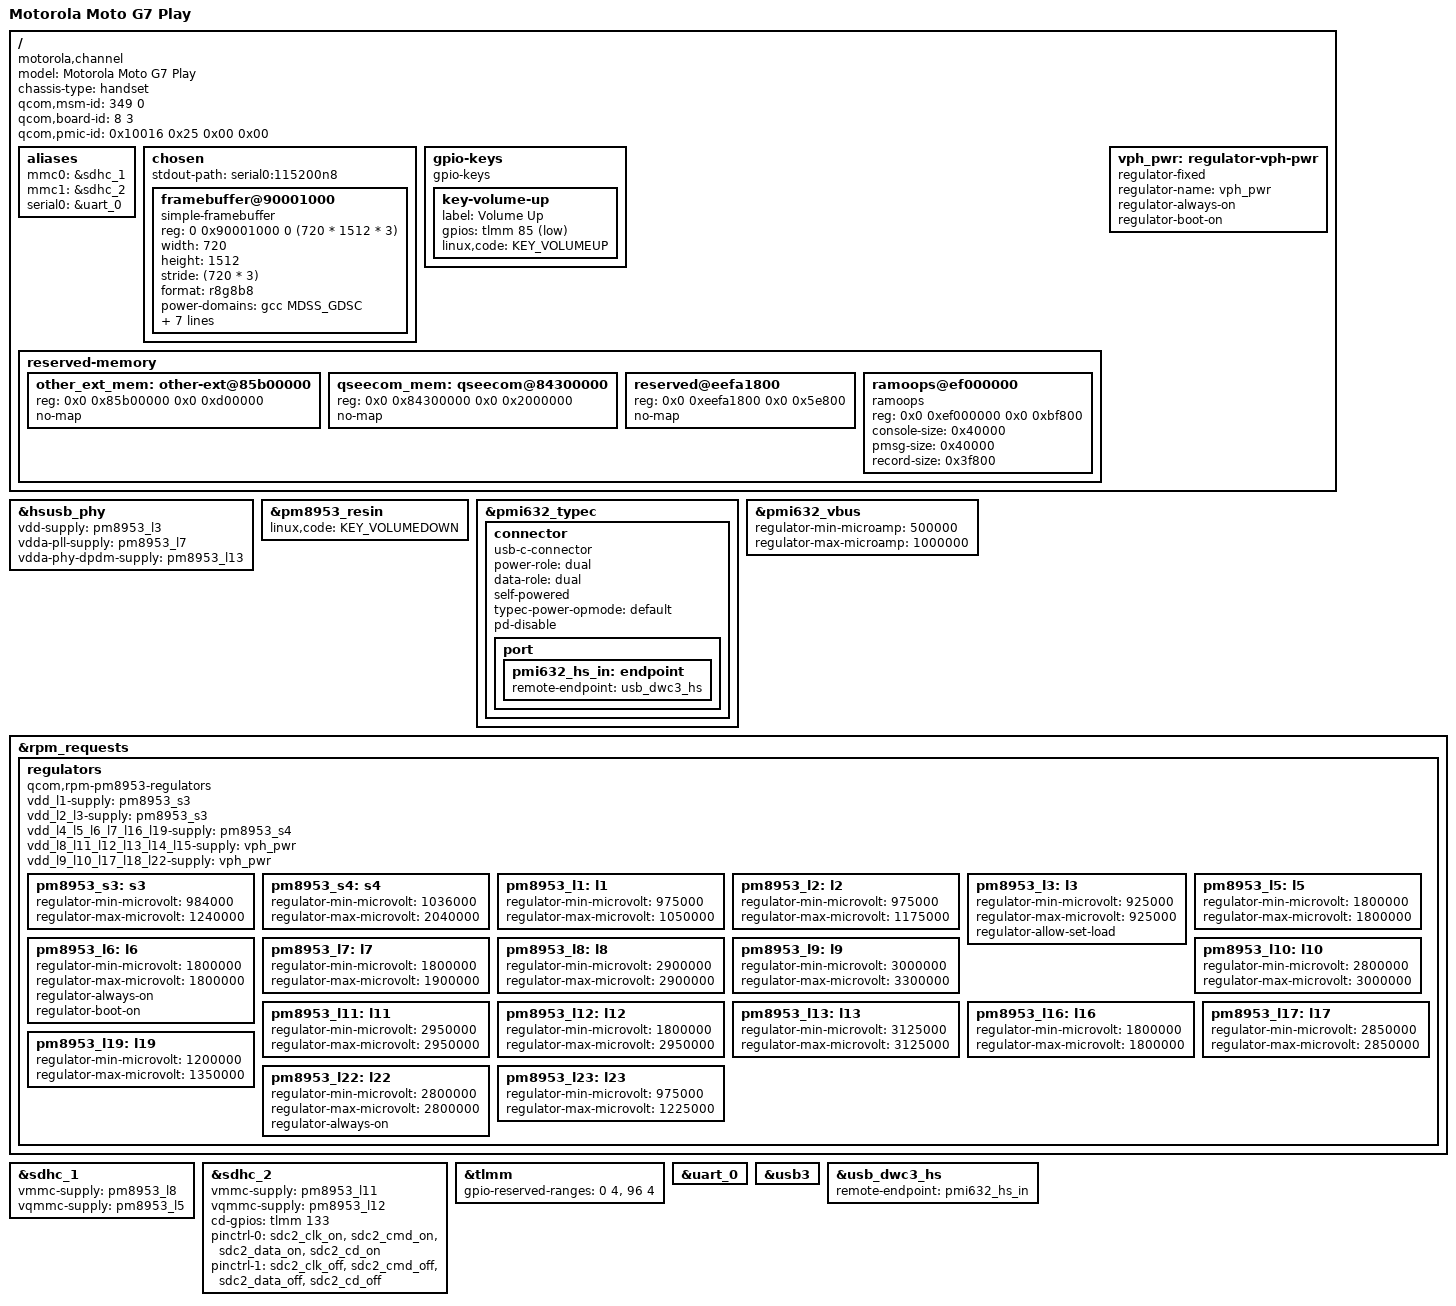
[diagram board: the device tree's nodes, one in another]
// SPDX-License-Identifier: BSD-3-Clause
/*
 * Copyright (c) 2026 Moto8953-Revived
 */

/dts-v1/;

#include "sdm632.dtsi"
#include "pm8953.dtsi"
#include "pmi632.dtsi"

/delete-node/ &qseecom_mem;

/ {
	model = "Motorola Moto G7 Play";
	compatible = "motorola,channel", "qcom,sdm632";
	chassis-type = "handset";

	/* Values from the Channel stock SDM632 + PMI632 MTP S3 DTB. */
	qcom,msm-id = <349 0>;
	qcom,board-id = <8 3>;
	qcom,pmic-id = <0x10016 0x25 0x00 0x00>;

	aliases {
		mmc0 = &sdhc_1;
		mmc1 = &sdhc_2;
		serial0 = &uart_0;
	};

	chosen {
		#address-cells = <2>;
		#size-cells = <2>;
		ranges;

		stdout-path = "serial0:115200n8";

		framebuffer@90001000 {
			compatible = "simple-framebuffer";
			reg = <0 0x90001000 0 (720 * 1512 * 3)>;
			width = <720>;
			height = <1512>;
			stride = <(720 * 3)>;
			format = "r8g8b8";

			power-domains = <&gcc MDSS_GDSC>;
			clocks = <&gcc GCC_MDSS_AHB_CLK>,
				 <&gcc GCC_MDSS_AXI_CLK>,
				 <&gcc GCC_MDSS_VSYNC_CLK>,
				 <&gcc GCC_MDSS_MDP_CLK>,
				 <&gcc GCC_MDSS_BYTE0_CLK>,
				 <&gcc GCC_MDSS_PCLK0_CLK>,
				 <&gcc GCC_MDSS_ESC0_CLK>;
		};
	};

	gpio-keys {
		compatible = "gpio-keys";

		key-volume-up {
			label = "Volume Up";
			gpios = <&tlmm 85 GPIO_ACTIVE_LOW>;
			linux,code = <KEY_VOLUMEUP>;
		};
	};

	reserved-memory {
		other_ext_mem: other-ext@85b00000 {
			reg = <0x0 0x85b00000 0x0 0xd00000>;
			no-map;
		};

		qseecom_mem: qseecom@84300000 {
			reg = <0x0 0x84300000 0x0 0x2000000>;
			no-map;
		};

		reserved@eefa1800 {
			reg = <0x0 0xeefa1800 0x0 0x5e800>;
			no-map;
		};

		ramoops@ef000000 {
			compatible = "ramoops";
			reg = <0x0 0xef000000 0x0 0xbf800>;
			console-size = <0x40000>;
			pmsg-size = <0x40000>;
			record-size = <0x3f800>;
		};
	};

	vph_pwr: regulator-vph-pwr {
		compatible = "regulator-fixed";
		regulator-name = "vph_pwr";
		regulator-always-on;
		regulator-boot-on;
	};
};

&hsusb_phy {
	vdd-supply = <&pm8953_l3>;
	vdda-pll-supply = <&pm8953_l7>;
	vdda-phy-dpdm-supply = <&pm8953_l13>;
	status = "okay";
};

&pm8953_resin {
	linux,code = <KEY_VOLUMEDOWN>;
	status = "okay";
};

&pmi632_typec {
	status = "okay";

	connector {
		compatible = "usb-c-connector";
		power-role = "dual";
		data-role = "dual";
		self-powered;
		typec-power-opmode = "default";
		pd-disable;

		port {
			pmi632_hs_in: endpoint {
				remote-endpoint = <&usb_dwc3_hs>;
			};
		};
	};
};

&pmi632_vbus {
	regulator-min-microamp = <500000>;
	regulator-max-microamp = <1000000>;
	status = "okay";
};

&rpm_requests {
	regulators {
		compatible = "qcom,rpm-pm8953-regulators";

		vdd_l1-supply = <&pm8953_s3>;
		vdd_l2_l3-supply = <&pm8953_s3>;
		vdd_l4_l5_l6_l7_l16_l19-supply = <&pm8953_s4>;
		vdd_l8_l11_l12_l13_l14_l15-supply = <&vph_pwr>;
		vdd_l9_l10_l17_l18_l22-supply = <&vph_pwr>;

		pm8953_s3: s3 {
			regulator-min-microvolt = <984000>;
			regulator-max-microvolt = <1240000>;
		};

		pm8953_s4: s4 {
			regulator-min-microvolt = <1036000>;
			regulator-max-microvolt = <2040000>;
		};

		pm8953_l1: l1 {
			regulator-min-microvolt = <975000>;
			regulator-max-microvolt = <1050000>;
		};

		pm8953_l2: l2 {
			regulator-min-microvolt = <975000>;
			regulator-max-microvolt = <1175000>;
		};

		pm8953_l3: l3 {
			regulator-min-microvolt = <925000>;
			regulator-max-microvolt = <925000>;
			regulator-allow-set-load;
		};

		pm8953_l5: l5 {
			regulator-min-microvolt = <1800000>;
			regulator-max-microvolt = <1800000>;
		};

		pm8953_l6: l6 {
			regulator-min-microvolt = <1800000>;
			regulator-max-microvolt = <1800000>;
			regulator-always-on;
			regulator-boot-on;
		};

		pm8953_l7: l7 {
			regulator-min-microvolt = <1800000>;
			regulator-max-microvolt = <1900000>;
		};

		pm8953_l8: l8 {
			regulator-min-microvolt = <2900000>;
			regulator-max-microvolt = <2900000>;
		};

		pm8953_l9: l9 {
			regulator-min-microvolt = <3000000>;
			regulator-max-microvolt = <3300000>;
		};

		pm8953_l10: l10 {
			regulator-min-microvolt = <2800000>;
			regulator-max-microvolt = <3000000>;
		};

		pm8953_l11: l11 {
			regulator-min-microvolt = <2950000>;
			regulator-max-microvolt = <2950000>;
		};

		pm8953_l12: l12 {
			regulator-min-microvolt = <1800000>;
			regulator-max-microvolt = <2950000>;
		};

		pm8953_l13: l13 {
			regulator-min-microvolt = <3125000>;
			regulator-max-microvolt = <3125000>;
		};

		pm8953_l16: l16 {
			regulator-min-microvolt = <1800000>;
			regulator-max-microvolt = <1800000>;
		};

		pm8953_l17: l17 {
			regulator-min-microvolt = <2850000>;
			regulator-max-microvolt = <2850000>;
		};

		pm8953_l19: l19 {
			regulator-min-microvolt = <1200000>;
			regulator-max-microvolt = <1350000>;
		};

		pm8953_l22: l22 {
			regulator-min-microvolt = <2800000>;
			regulator-max-microvolt = <2800000>;
			regulator-always-on;
		};

		pm8953_l23: l23 {
			regulator-min-microvolt = <975000>;
			regulator-max-microvolt = <1225000>;
		};
	};
};

&sdhc_1 {
	vmmc-supply = <&pm8953_l8>;
	vqmmc-supply = <&pm8953_l5>;
	status = "okay";
};

&sdhc_2 {
	vmmc-supply = <&pm8953_l11>;
	vqmmc-supply = <&pm8953_l12>;

	cd-gpios = <&tlmm 133 GPIO_ACTIVE_HIGH>;

	pinctrl-names = "default", "sleep";
	pinctrl-0 = <&sdc2_clk_on &sdc2_cmd_on &sdc2_data_on &sdc2_cd_on>;
	pinctrl-1 = <&sdc2_clk_off &sdc2_cmd_off &sdc2_data_off &sdc2_cd_off>;

	status = "okay";
};

&tlmm {
	/*
	 * 0-3 are commonly TZ-owned across the msm8953 family and 96-99
	 * are reserved on the sibling SDM632 Motorola boards. Exact
	 * Channel ownership is unverified; nothing enabled here uses them.
	 */
	gpio-reserved-ranges = <0 4>, <96 4>;
};

&uart_0 {
	status = "okay";
};

&usb3 {
	status = "okay";
};

&usb_dwc3_hs {
	remote-endpoint = <&pmi632_hs_in>;
};
